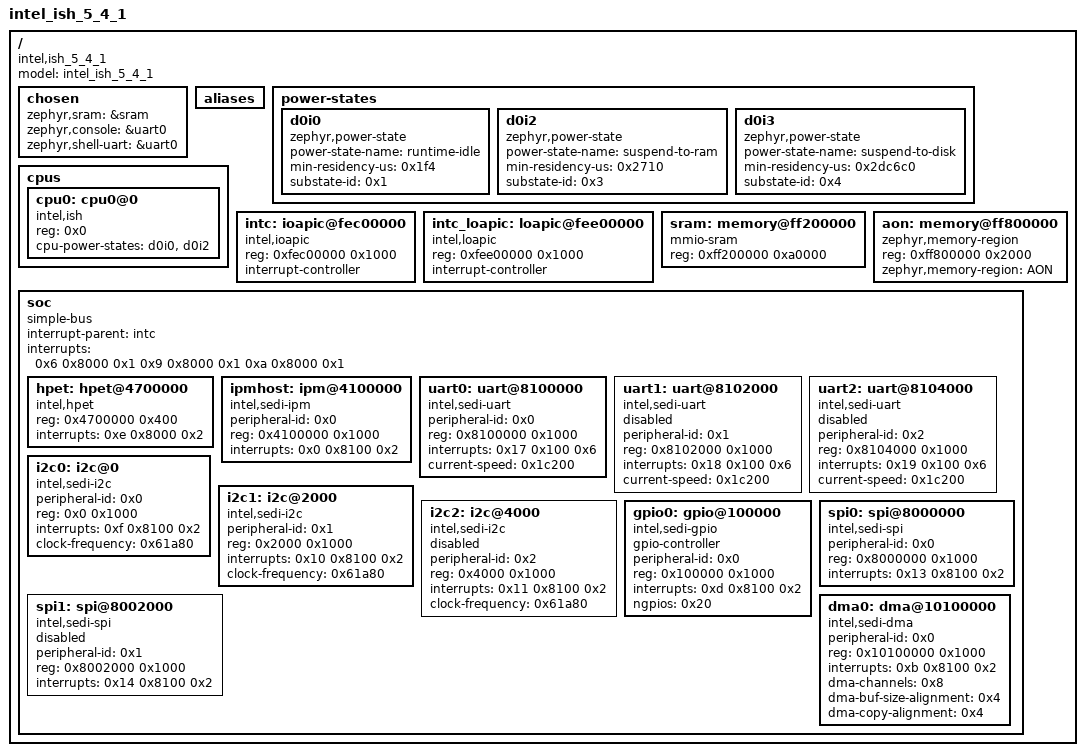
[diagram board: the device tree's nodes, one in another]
/dts-v1/;

/* node '/' defined in zephyr/dts/common/skeleton.dtsi:9 */
/ {
	#address-cells = < 0x1 >;       /* in zephyr/dts/common/skeleton.dtsi:10 */
	#size-cells = < 0x1 >;          /* in zephyr/dts/common/skeleton.dtsi:11 */
	model = "intel_ish_5_4_1";      /* in zephyr/boards/intel/ish/intel_ish_5_4_1.dts:12 */
	compatible = "intel,ish_5_4_1"; /* in zephyr/boards/intel/ish/intel_ish_5_4_1.dts:13 */

	/* node '/chosen' defined in zephyr/dts/common/skeleton.dtsi:13 */
	chosen {
		zephyr,sram = &sram;        /* in zephyr/boards/intel/ish/intel_ish_5_4_1.dts:16 */
		zephyr,console = &uart0;    /* in zephyr/boards/intel/ish/intel_ish_5_4_1.dts:17 */
		zephyr,shell-uart = &uart0; /* in zephyr/boards/intel/ish/intel_ish_5_4_1.dts:18 */
	};

	/* node '/aliases' defined in zephyr/dts/common/skeleton.dtsi:15 */
	aliases {
	};

	/* node '/power-states' defined in zephyr/dts/x86/intel/intel_ish5.dtsi:13 */
	power-states {

		/* node '/power-states/d0i0' defined in zephyr/dts/x86/intel/intel_ish5.dtsi:14 */
		d0i0: d0i0 {
			compatible = "zephyr,power-state"; /* in zephyr/dts/x86/intel/intel_ish5.dtsi:15 */
			power-state-name = "runtime-idle"; /* in zephyr/dts/x86/intel/intel_ish5.dtsi:16 */
			min-residency-us = < 0x1f4 >;      /* in zephyr/dts/x86/intel/intel_ish5.dtsi:17 */
			substate-id = < 0x1 >;             /* in zephyr/dts/x86/intel/intel_ish5.dtsi:18 */
			phandle = < 0x1 >;                 /* in zephyr/dts/x86/intel/intel_ish5.dtsi:44 */
		};

		/* node '/power-states/d0i2' defined in zephyr/dts/x86/intel/intel_ish5.dtsi:21 */
		d0i2: d0i2 {
			compatible = "zephyr,power-state";   /* in zephyr/dts/x86/intel/intel_ish5.dtsi:22 */
			power-state-name = "suspend-to-ram"; /* in zephyr/dts/x86/intel/intel_ish5.dtsi:23 */
			min-residency-us = < 0x2710 >;       /* in zephyr/dts/x86/intel/intel_ish5.dtsi:24 */
			substate-id = < 0x3 >;               /* in zephyr/dts/x86/intel/intel_ish5.dtsi:25 */
			phandle = < 0x2 >;                   /* in zephyr/dts/x86/intel/intel_ish5.dtsi:44 */
		};

		/* node '/power-states/d0i3' defined in zephyr/dts/x86/intel/intel_ish5.dtsi:28 */
		d0i3: d0i3 {
			compatible = "zephyr,power-state";    /* in zephyr/dts/x86/intel/intel_ish5.dtsi:29 */
			power-state-name = "suspend-to-disk"; /* in zephyr/dts/x86/intel/intel_ish5.dtsi:30 */
			min-residency-us = < 0x2dc6c0 >;      /* in zephyr/dts/x86/intel/intel_ish5.dtsi:31 */
			substate-id = < 0x4 >;                /* in zephyr/dts/x86/intel/intel_ish5.dtsi:32 */
		};
	};

	/* node '/cpus' defined in zephyr/dts/x86/intel/intel_ish5.dtsi:36 */
	cpus {
		#address-cells = < 0x1 >; /* in zephyr/dts/x86/intel/intel_ish5.dtsi:37 */
		#size-cells = < 0x0 >;    /* in zephyr/dts/x86/intel/intel_ish5.dtsi:38 */

		/* node '/cpus/cpu0@0' defined in zephyr/dts/x86/intel/intel_ish5.dtsi:40 */
		cpu0: cpu0@0 {
			device_type = "cpu";                /* in zephyr/dts/x86/intel/intel_ish5.dtsi:41 */
			compatible = "intel,ish",
			             "intel,x86";           /* in zephyr/dts/x86/intel/intel_ish5.dtsi:42 */
			reg = < 0x0 >;                      /* in zephyr/dts/x86/intel/intel_ish5.dtsi:43 */
			cpu-power-states = < &d0i0 &d0i2 >; /* in zephyr/dts/x86/intel/intel_ish5.dtsi:44 */
		};
	};

	/* node '/ioapic@fec00000' defined in zephyr/dts/x86/intel/intel_ish5.dtsi:48 */
	intc: ioapic@fec00000 {
		compatible = "intel,ioapic"; /* in zephyr/dts/x86/intel/intel_ish5.dtsi:49 */
		#address-cells = < 0x1 >;    /* in zephyr/dts/x86/intel/intel_ish5.dtsi:50 */
		#interrupt-cells = < 0x3 >;  /* in zephyr/dts/x86/intel/intel_ish5.dtsi:51 */
		reg = < 0xfec00000 0x1000 >; /* in zephyr/dts/x86/intel/intel_ish5.dtsi:52 */
		interrupt-controller;        /* in zephyr/dts/x86/intel/intel_ish5.dtsi:53 */
		phandle = < 0x3 >;           /* in zephyr/dts/x86/intel/intel_ish5.dtsi:82 */
	};

	/* node '/loapic@fee00000' defined in zephyr/dts/x86/intel/intel_ish5.dtsi:56 */
	intc_loapic: loapic@fee00000 {
		compatible = "intel,loapic"; /* in zephyr/dts/x86/intel/intel_ish5.dtsi:57 */
		reg = < 0xfee00000 0x1000 >; /* in zephyr/dts/x86/intel/intel_ish5.dtsi:58 */
		interrupt-controller;        /* in zephyr/dts/x86/intel/intel_ish5.dtsi:59 */
		#interrupt-cells = < 0x3 >;  /* in zephyr/dts/x86/intel/intel_ish5.dtsi:60 */
		#address-cells = < 0x1 >;    /* in zephyr/dts/x86/intel/intel_ish5.dtsi:61 */
	};

	/* node '/memory@ff200000' defined in zephyr/dts/x86/intel/intel_ish5.dtsi:64 */
	sram: memory@ff200000 {
		device_type = "memory";       /* in zephyr/dts/x86/intel/intel_ish5.dtsi:65 */
		compatible = "mmio-sram";     /* in zephyr/dts/x86/intel/intel_ish5.dtsi:66 */
		reg = < 0xff200000 0xa0000 >; /* in zephyr/dts/x86/intel/intel_ish5.dtsi:67 */
	};

	/* node '/memory@ff800000' defined in zephyr/dts/x86/intel/intel_ish5.dtsi:70 */
	aon: memory@ff800000 {
		device_type = "memory";              /* in zephyr/dts/x86/intel/intel_ish5.dtsi:71 */
		compatible = "zephyr,memory-region",
		             "mmio-sram";            /* in zephyr/dts/x86/intel/intel_ish5.dtsi:72 */
		reg = < 0xff800000 0x2000 >;         /* in zephyr/dts/x86/intel/intel_ish5.dtsi:73 */
		zephyr,memory-region = "AON";        /* in zephyr/dts/x86/intel/intel_ish5.dtsi:74 */
	};

	/* node '/soc' defined in zephyr/dts/x86/intel/intel_ish5.dtsi:77 */
	soc: soc {
		#address-cells = < 0x1 >;                                      /* in zephyr/dts/x86/intel/intel_ish5.dtsi:78 */
		#size-cells = < 0x1 >;                                         /* in zephyr/dts/x86/intel/intel_ish5.dtsi:79 */
		#interrupt-cells = < 0x3 >;                                    /* in zephyr/dts/x86/intel/intel_ish5.dtsi:80 */
		compatible = "simple-bus";                                     /* in zephyr/dts/x86/intel/intel_ish5.dtsi:81 */
		interrupt-parent = < &intc >;                                  /* in zephyr/dts/x86/intel/intel_ish5.dtsi:82 */
		interrupts = < 0x6 0x8000 0x1 0x9 0x8000 0x1 0xa 0x8000 0x1 >; /* in zephyr/dts/x86/intel/intel_ish5.dtsi:83 */
		interrupt-names = "reset_prep",
		                  "pcidev",
		                  "pmu2ioapic";                                /* in zephyr/dts/x86/intel/intel_ish5.dtsi:88 */
		ranges;                                                        /* in zephyr/dts/x86/intel/intel_ish5.dtsi:89 */

		/* node '/soc/hpet@4700000' defined in zephyr/dts/x86/intel/intel_ish5.dtsi:91 */
		hpet: hpet@4700000 {
			compatible = "intel,hpet";       /* in zephyr/dts/x86/intel/intel_ish5.dtsi:92 */
			reg = < 0x4700000 0x400 >;       /* in zephyr/dts/x86/intel/intel_ish5.dtsi:93 */
			interrupts = < 0xe 0x8000 0x2 >; /* in zephyr/dts/x86/intel/intel_ish5.dtsi:94 */
			status = "okay";                 /* in zephyr/dts/x86/intel/intel_ish5.dtsi:96 */
		};

		/* node '/soc/ipm@4100000' defined in zephyr/dts/x86/intel/intel_ish5.dtsi:99 */
		ipmhost: ipm@4100000 {
			compatible = "intel,sedi-ipm";   /* in zephyr/dts/x86/intel/intel_ish5.dtsi:100 */
			peripheral-id = < 0x0 >;         /* in zephyr/dts/x86/intel/intel_ish5.dtsi:101 */
			reg = < 0x4100000 0x1000 >;      /* in zephyr/dts/x86/intel/intel_ish5.dtsi:102 */
			interrupts = < 0x0 0x8100 0x2 >; /* in zephyr/dts/x86/intel/intel_ish5.dtsi:103 */
			status = "okay";                 /* in zephyr/dts/x86/intel/intel_ish5.dtsi:105 */
		};

		/* node '/soc/uart@8100000' defined in zephyr/dts/x86/intel/intel_ish5.dtsi:108 */
		uart0: uart@8100000 {
			compatible = "intel,sedi-uart";  /* in zephyr/dts/x86/intel/intel_ish5.dtsi:109 */
			peripheral-id = < 0x0 >;         /* in zephyr/dts/x86/intel/intel_ish5.dtsi:110 */
			reg = < 0x8100000 0x1000 >;      /* in zephyr/dts/x86/intel/intel_ish5.dtsi:111 */
			interrupts = < 0x17 0x100 0x6 >; /* in zephyr/dts/x86/intel/intel_ish5.dtsi:112 */
			status = "okay";                 /* in zephyr/dts/x86/intel/intel_ish5.dtsi:114 */
			current-speed = < 0x1c200 >;     /* in zephyr/dts/x86/intel/intel_ish5.dtsi:115 */
		};

		/* node '/soc/uart@8102000' defined in zephyr/dts/x86/intel/intel_ish5.dtsi:118 */
		uart1: uart@8102000 {
			compatible = "intel,sedi-uart";  /* in zephyr/dts/x86/intel/intel_ish5.dtsi:119 */
			peripheral-id = < 0x1 >;         /* in zephyr/dts/x86/intel/intel_ish5.dtsi:120 */
			reg = < 0x8102000 0x1000 >;      /* in zephyr/dts/x86/intel/intel_ish5.dtsi:121 */
			interrupts = < 0x18 0x100 0x6 >; /* in zephyr/dts/x86/intel/intel_ish5.dtsi:122 */
			status = "disabled";             /* in zephyr/dts/x86/intel/intel_ish5.dtsi:124 */
			current-speed = < 0x1c200 >;     /* in zephyr/dts/x86/intel/intel_ish5.dtsi:125 */
		};

		/* node '/soc/uart@8104000' defined in zephyr/dts/x86/intel/intel_ish5.dtsi:128 */
		uart2: uart@8104000 {
			compatible = "intel,sedi-uart";  /* in zephyr/dts/x86/intel/intel_ish5.dtsi:129 */
			peripheral-id = < 0x2 >;         /* in zephyr/dts/x86/intel/intel_ish5.dtsi:130 */
			reg = < 0x8104000 0x1000 >;      /* in zephyr/dts/x86/intel/intel_ish5.dtsi:131 */
			interrupts = < 0x19 0x100 0x6 >; /* in zephyr/dts/x86/intel/intel_ish5.dtsi:132 */
			status = "disabled";             /* in zephyr/dts/x86/intel/intel_ish5.dtsi:134 */
			current-speed = < 0x1c200 >;     /* in zephyr/dts/x86/intel/intel_ish5.dtsi:135 */
		};

		/* node '/soc/i2c@0' defined in zephyr/dts/x86/intel/intel_ish5.dtsi:138 */
		i2c0: i2c@0 {
			compatible = "intel,sedi-i2c";   /* in zephyr/dts/x86/intel/intel_ish5.dtsi:139 */
			peripheral-id = < 0x0 >;         /* in zephyr/dts/x86/intel/intel_ish5.dtsi:140 */
			#address-cells = < 0x1 >;        /* in zephyr/dts/x86/intel/intel_ish5.dtsi:141 */
			#size-cells = < 0x0 >;           /* in zephyr/dts/x86/intel/intel_ish5.dtsi:142 */
			reg = < 0x0 0x1000 >;            /* in zephyr/dts/x86/intel/intel_ish5.dtsi:143 */
			interrupts = < 0xf 0x8100 0x2 >; /* in zephyr/dts/x86/intel/intel_ish5.dtsi:144 */
			status = "okay";                 /* in zephyr/dts/x86/intel/intel_ish5.dtsi:146 */
			clock-frequency = < 0x61a80 >;   /* in zephyr/dts/x86/intel/intel_ish5.dtsi:147 */
		};

		/* node '/soc/i2c@2000' defined in zephyr/dts/x86/intel/intel_ish5.dtsi:150 */
		i2c1: i2c@2000 {
			compatible = "intel,sedi-i2c";    /* in zephyr/dts/x86/intel/intel_ish5.dtsi:151 */
			peripheral-id = < 0x1 >;          /* in zephyr/dts/x86/intel/intel_ish5.dtsi:152 */
			#address-cells = < 0x1 >;         /* in zephyr/dts/x86/intel/intel_ish5.dtsi:153 */
			#size-cells = < 0x0 >;            /* in zephyr/dts/x86/intel/intel_ish5.dtsi:154 */
			reg = < 0x2000 0x1000 >;          /* in zephyr/dts/x86/intel/intel_ish5.dtsi:155 */
			interrupts = < 0x10 0x8100 0x2 >; /* in zephyr/dts/x86/intel/intel_ish5.dtsi:156 */
			status = "okay";                  /* in zephyr/dts/x86/intel/intel_ish5.dtsi:158 */
			clock-frequency = < 0x61a80 >;    /* in zephyr/dts/x86/intel/intel_ish5.dtsi:159 */
		};

		/* node '/soc/i2c@4000' defined in zephyr/dts/x86/intel/intel_ish5.dtsi:162 */
		i2c2: i2c@4000 {
			compatible = "intel,sedi-i2c";    /* in zephyr/dts/x86/intel/intel_ish5.dtsi:163 */
			peripheral-id = < 0x2 >;          /* in zephyr/dts/x86/intel/intel_ish5.dtsi:164 */
			#address-cells = < 0x1 >;         /* in zephyr/dts/x86/intel/intel_ish5.dtsi:165 */
			#size-cells = < 0x0 >;            /* in zephyr/dts/x86/intel/intel_ish5.dtsi:166 */
			reg = < 0x4000 0x1000 >;          /* in zephyr/dts/x86/intel/intel_ish5.dtsi:167 */
			interrupts = < 0x11 0x8100 0x2 >; /* in zephyr/dts/x86/intel/intel_ish5.dtsi:168 */
			status = "disabled";              /* in zephyr/dts/x86/intel/intel_ish5.dtsi:170 */
			clock-frequency = < 0x61a80 >;    /* in zephyr/dts/x86/intel/intel_ish5.dtsi:171 */
		};

		/* node '/soc/gpio@100000' defined in zephyr/dts/x86/intel/intel_ish5.dtsi:174 */
		gpio0: gpio@100000 {
			compatible = "intel,sedi-gpio";  /* in zephyr/dts/x86/intel/intel_ish5.dtsi:175 */
			gpio-controller;                 /* in zephyr/dts/x86/intel/intel_ish5.dtsi:176 */
			#gpio-cells = < 0x2 >;           /* in zephyr/dts/x86/intel/intel_ish5.dtsi:177 */
			peripheral-id = < 0x0 >;         /* in zephyr/dts/x86/intel/intel_ish5.dtsi:178 */
			reg = < 0x100000 0x1000 >;       /* in zephyr/dts/x86/intel/intel_ish5.dtsi:179 */
			interrupts = < 0xd 0x8100 0x2 >; /* in zephyr/dts/x86/intel/intel_ish5.dtsi:180 */
			ngpios = < 0x20 >;               /* in zephyr/dts/x86/intel/intel_ish5.dtsi:181 */
			status = "okay";                 /* in zephyr/dts/x86/intel/intel_ish5.dtsi:183 */
		};

		/* node '/soc/spi@8000000' defined in zephyr/dts/x86/intel/intel_ish5.dtsi:186 */
		spi0: spi@8000000 {
			compatible = "intel,sedi-spi";    /* in zephyr/dts/x86/intel/intel_ish5.dtsi:187 */
			peripheral-id = < 0x0 >;          /* in zephyr/dts/x86/intel/intel_ish5.dtsi:188 */
			#address-cells = < 0x1 >;         /* in zephyr/dts/x86/intel/intel_ish5.dtsi:189 */
			#size-cells = < 0x0 >;            /* in zephyr/dts/x86/intel/intel_ish5.dtsi:190 */
			reg = < 0x8000000 0x1000 >;       /* in zephyr/dts/x86/intel/intel_ish5.dtsi:191 */
			interrupts = < 0x13 0x8100 0x2 >; /* in zephyr/dts/x86/intel/intel_ish5.dtsi:192 */
			status = "okay";                  /* in zephyr/dts/x86/intel/intel_ish5.dtsi:194 */
		};

		/* node '/soc/spi@8002000' defined in zephyr/dts/x86/intel/intel_ish5.dtsi:197 */
		spi1: spi@8002000 {
			compatible = "intel,sedi-spi";    /* in zephyr/dts/x86/intel/intel_ish5.dtsi:198 */
			peripheral-id = < 0x1 >;          /* in zephyr/dts/x86/intel/intel_ish5.dtsi:199 */
			#address-cells = < 0x1 >;         /* in zephyr/dts/x86/intel/intel_ish5.dtsi:200 */
			#size-cells = < 0x0 >;            /* in zephyr/dts/x86/intel/intel_ish5.dtsi:201 */
			reg = < 0x8002000 0x1000 >;       /* in zephyr/dts/x86/intel/intel_ish5.dtsi:202 */
			interrupts = < 0x14 0x8100 0x2 >; /* in zephyr/dts/x86/intel/intel_ish5.dtsi:203 */
			status = "disabled";              /* in zephyr/dts/x86/intel/intel_ish5.dtsi:205 */
		};

		/* node '/soc/dma@10100000' defined in zephyr/dts/x86/intel/intel_ish5.dtsi:208 */
		dma0: dma@10100000 {
			compatible = "intel,sedi-dma";    /* in zephyr/dts/x86/intel/intel_ish5.dtsi:209 */
			peripheral-id = < 0x0 >;          /* in zephyr/dts/x86/intel/intel_ish5.dtsi:210 */
			reg = < 0x10100000 0x1000 >;      /* in zephyr/dts/x86/intel/intel_ish5.dtsi:211 */
			interrupts = < 0xb 0x8100 0x2 >;  /* in zephyr/dts/x86/intel/intel_ish5.dtsi:212 */
			#dma-cells = < 0x2 >;             /* in zephyr/dts/x86/intel/intel_ish5.dtsi:213 */
			dma-channels = < 0x8 >;           /* in zephyr/dts/x86/intel/intel_ish5.dtsi:214 */
			dma-buf-size-alignment = < 0x4 >; /* in zephyr/dts/x86/intel/intel_ish5.dtsi:215 */
			dma-copy-alignment = < 0x4 >;     /* in zephyr/dts/x86/intel/intel_ish5.dtsi:216 */
			status = "okay";                  /* in zephyr/dts/x86/intel/intel_ish5.dtsi:218 */
		};
	};
};
